VERSION ""

NS_ :

BS_:

BU_: XXX

BO_ 85 CID_PEUIZP: 8 XXX
 SG_ sig_yvqqxy : 40|1@1+ (1,0) [0|1] "" XXX
 SG_ sig_idcafi : 56|8@1+ (1,0) [0|255] "" XXX

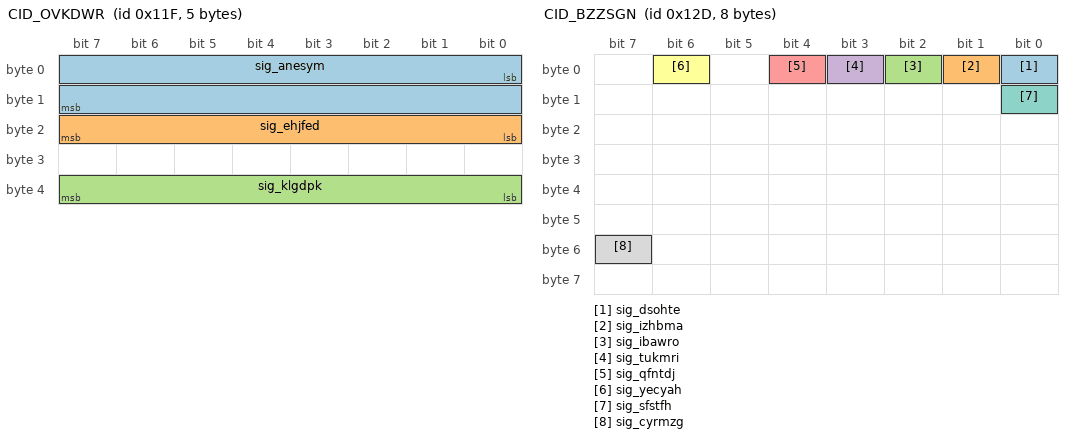
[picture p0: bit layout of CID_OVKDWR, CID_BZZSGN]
BO_ 287 CID_OVKDWR: 5 XXX
 SG_ sig_anesym : 0|16@1- (0.1,0) [-450|450] "" XXX
 SG_ sig_ehjfed : 16|8@1+ (4,0) [0|1020] "" XXX
 SG_ sig_klgdpk : 32|8@1+ (1,0) [0|255] "" XXX

BO_ 289 CID_AORLKS: 8 XXX
 SG_ sig_fkcpll : 0|12@1+ (1,0) [0|255] "" XXX

BO_ 301 CID_BZZSGN: 8 XXX
 SG_ sig_dsohte : 0|1@0+ (1,0) [0|1] "" XXX
 SG_ sig_izhbma : 1|1@0+ (1,0) [0|1] "" XXX
 SG_ sig_ibawro : 2|1@0+ (1,0) [0|1] "" XXX
 SG_ sig_tukmri : 3|1@0+ (1,0) [0|1] "" XXX
 SG_ sig_qfntdj : 4|1@0+ (1,0) [0|1] "" XXX
 SG_ sig_yecyah : 6|1@0+ (1,0) [0|1] "" XXX
 SG_ sig_sfstfh : 8|1@0+ (1,0) [0|1] "" XXX
 SG_ sig_cyrmzg : 55|1@0+ (1,0) [0|1] "" XXX

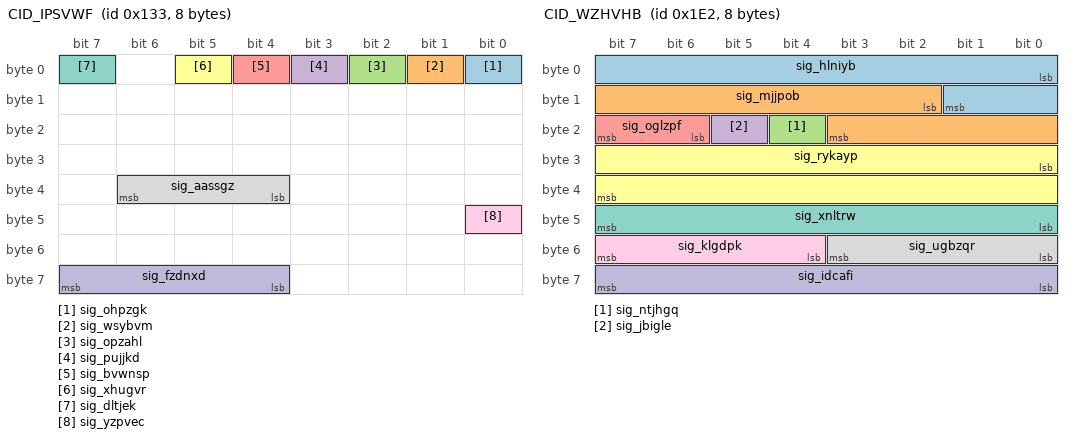
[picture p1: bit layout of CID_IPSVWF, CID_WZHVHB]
BO_ 307 CID_IPSVWF: 8 XXX
 SG_ sig_ohpzgk : 0|1@0+ (1,0) [0|1] "" XXX
 SG_ sig_wsybvm : 1|1@1+ (1,0) [0|1] "" XXX
 SG_ sig_opzahl : 2|1@1+ (1,0) [0|1] "" XXX
 SG_ sig_pujjkd : 3|1@1+ (1,0) [0|1] "" XXX
 SG_ sig_bvwnsp : 4|1@0+ (1,0) [0|1] "" XXX
 SG_ sig_xhugvr : 5|1@0+ (1,0) [0|1] "" XXX
 SG_ sig_dltjek : 7|1@0+ (1,0) [0|1] "" XXX
 SG_ sig_aassgz : 36|3@1+ (1,0) [0|7] "" XXX
 SG_ sig_yzpvec : 40|1@0+ (1,0) [0|1] "" XXX
 SG_ sig_fzdnxd : 63|4@0+ (1,0) [0|15] "" XXX

BO_ 482 CID_WZHVHB: 8 XXX
 SG_ sig_hlniyb : 0|10@1- (0.01,0) [0|5] "" XXX
 SG_ sig_mjjpob : 10|10@1- (0.01,0) [-5|0] "" XXX
 SG_ sig_ntjhgq : 20|1@0+ (1,0) [0|1] "" XXX
 SG_ sig_jbigle : 21|1@0+ (1,0) [0|1] "" XXX
 SG_ sig_oglzpf : 22|2@1+ (1,0) [0|1] "" XXX
 SG_ sig_rykayp : 24|16@1- (0.1,0) [-780|779.9] "" XXX
 SG_ sig_xnltrw : 47|8@0+ (1,0) [0|255] "" XXX
 SG_ sig_ugbzqr : 48|4@1+ (1,0) [0|15] "" XXX
 SG_ sig_klgdpk : 52|4@1+ (1,0) [0|15] "" XXX
 SG_ sig_idcafi : 56|8@1+ (1,0) [0|255] "" XXX

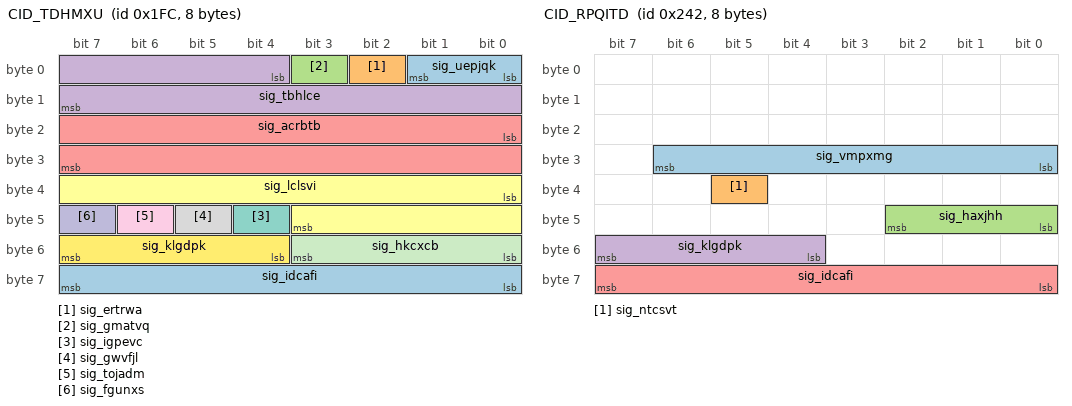
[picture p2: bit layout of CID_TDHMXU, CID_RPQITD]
BO_ 508 CID_TDHMXU: 8 XXX
 SG_ sig_uepjqk : 0|2@1+ (1,0) [0|1] "" XXX
 SG_ sig_ertrwa : 2|1@1+ (1,0) [0|1] "" XXX
 SG_ sig_gmatvq : 3|1@0+ (1,0) [0|1] "" XXX
 SG_ sig_tbhlce : 4|12@1- (1,0) [-2048|2047] "" XXX
 SG_ sig_acrbtb : 16|16@1- (0.1,0) [-780|779.9] "Deg" XXX
 SG_ sig_lclsvi : 32|12@1- (1,0) [0|63] "" XXX
 SG_ sig_igpevc : 44|1@0+ (1,0) [0|1] "" XXX
 SG_ sig_gwvfjl : 45|1@1+ (1,0) [0|255] "" XXX
 SG_ sig_tojadm : 46|1@1+ (1,0) [0|1] "" XXX
 SG_ sig_fgunxs : 47|1@0+ (1,0) [0|3] "" XXX
 SG_ sig_hkcxcb : 48|4@1+ (1,0) [0|15] "" XXX
 SG_ sig_klgdpk : 52|4@1+ (1,0) [0|15] "" XXX
 SG_ sig_idcafi : 56|8@1+ (1,0) [0|255] "" XXX

BO_ 578 CID_RPQITD: 8 XXX
 SG_ sig_vmpxmg : 30|7@0+ (1,0) [0|127] "" XXX
 SG_ sig_ntcsvt : 37|1@0+ (1,0) [0|1] "" XXX
 SG_ sig_haxjhh : 40|3@1+ (1,0) [0|7] "" XXX
 SG_ sig_klgdpk : 55|4@0+ (1,0) [0|15] "" XXX
 SG_ sig_idcafi : 56|8@1+ (1,0) [0|255] "" XXX

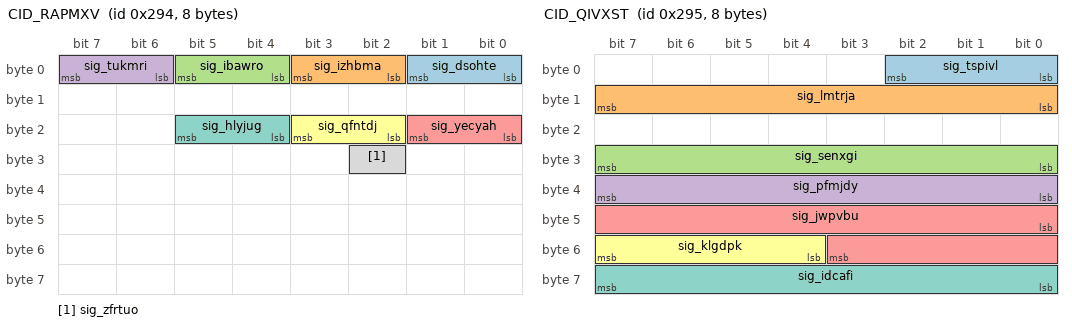
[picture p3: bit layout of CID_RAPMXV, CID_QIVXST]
BO_ 660 CID_RAPMXV: 8 XXX
 SG_ sig_dsohte : 1|2@0+ (1,0) [0|3] "" XXX
 SG_ sig_izhbma : 3|2@0+ (1,0) [0|3] "" XXX
 SG_ sig_ibawro : 5|2@0+ (1,0) [0|3] "" XXX
 SG_ sig_tukmri : 7|2@0+ (1,0) [0|3] "" XXX
 SG_ sig_yecyah : 17|2@0+ (1,0) [0|3] "" XXX
 SG_ sig_qfntdj : 19|2@0+ (1,0) [0|3] "" XXX
 SG_ sig_hlyjug : 21|2@0+ (1,0) [0|3] "" XXX
 SG_ sig_zfrtuo : 26|1@0+ (1,0) [0|1] "" XXX

BO_ 661 CID_QIVXST: 8 XXX
 SG_ sig_tspivl : 2|3@0+ (1,0) [0|7] "" XXX
 SG_ sig_lmtrja : 15|8@0+ (1,0) [0|255] "" XXX
 SG_ sig_senxgi : 31|8@0+ (1,0) [0|255] "" XXX
 SG_ sig_pfmjdy : 32|8@1+ (1,0) [0|255] "" XXX
 SG_ sig_jwpvbu : 40|12@1+ (1,0) [0|255] "" XXX
 SG_ sig_klgdpk : 52|4@1+ (1,0) [0|15] "" XXX
 SG_ sig_idcafi : 63|8@0+ (1,0) [0|255] "" XXX

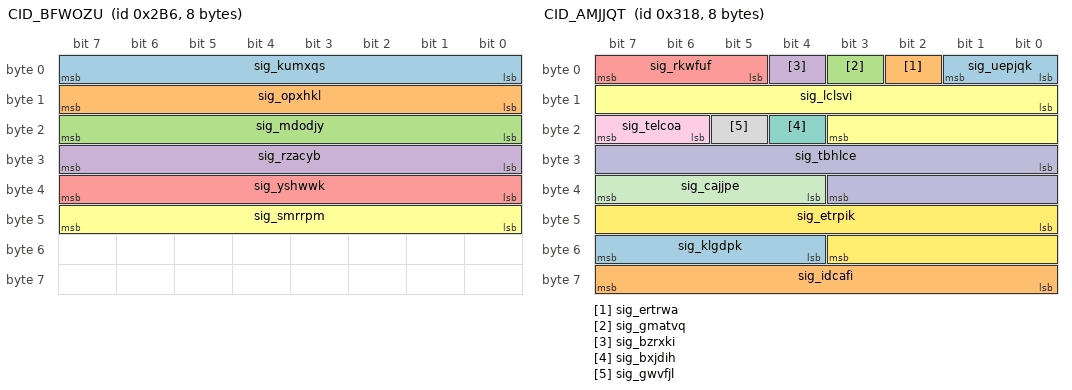
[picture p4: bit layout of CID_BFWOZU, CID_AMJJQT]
BO_ 694 CID_BFWOZU: 8 XXX
 SG_ sig_kumxqs : 7|8@0+ (1,0) [0|255] "" XXX
 SG_ sig_opxhkl : 15|8@0+ (1,0) [0|255] "" XXX
 SG_ sig_mdodjy : 23|8@0+ (1,0) [0|255] "" XXX
 SG_ sig_rzacyb : 31|8@0+ (1,0) [0|255] "" XXX
 SG_ sig_yshwwk : 39|8@0+ (1,0) [0|255] "" XXX
 SG_ sig_smrrpm : 47|8@0+ (1,0) [0|255] "" XXX

BO_ 790 CID_TVLKQR: 8 XXX
 SG_ sig_jftqug : 3|4@0+ (1,0) [0|1] "" XXX
 SG_ sig_bzrfrl : 4|2@1+ (1,0) [0|3] "" XXX
 SG_ sig_kjuwjn : 6|2@1+ (1,0) [0|3] "" XXX
 SG_ sig_vzitdr : 8|2@1+ (1,0) [0|3] "" XXX
 SG_ sig_mcuwzq : 10|1@1+ (1,0) [0|1] "" XXX
 SG_ sig_qhufxf : 11|4@1+ (1,0) [0|1] "" XXX
 SG_ sig_bguwph : 15|1@0+ (1,0) [0|1] "" XXX
 SG_ sig_rykayp : 16|11@1- (1,0) [-1024|1023] "" XXX
 SG_ sig_ntjhgq : 27|1@1+ (1,0) [0|1] "" XXX
 SG_ sig_jbigle : 28|1@1+ (1,0) [0|3] "" XXX
 SG_ sig_umrrjl : 29|1@0+ (1,0) [0|1] "" XXX
 SG_ sig_vdsypr : 30|1@0+ (1,0) [0|1] "" XXX
 SG_ sig_nazuvq : 31|1@0+ (1,0) [0|1] "" XXX
 SG_ sig_bxkagn : 32|2@1+ (1,0) [0|3] "" XXX
 SG_ sig_rsbhym : 34|2@1+ (1,0) [0|3] "" XXX
 SG_ sig_kmgogh : 36|4@1+ (1,0) [0|3] "" XXX
 SG_ sig_vwzhux : 40|8@1+ (5,-5) [-5|1270] "" XXX
 SG_ sig_emoqdt : 49|2@0+ (1,0) [0|3] "" XXX
 SG_ sig_bosbbj : 51|2@0+ (1,0) [0|3] "" XXX
 SG_ sig_klgdpk : 52|4@1+ (1,0) [0|15] "" XXX
 SG_ sig_idcafi : 56|8@1+ (1,0) [0|15] "" XXX

BO_ 792 CID_AMJJQT: 8 XXX
 SG_ sig_uepjqk : 0|2@1+ (1,0) [0|1] "" XXX
 SG_ sig_ertrwa : 2|1@1+ (1,0) [0|1] "" XXX
 SG_ sig_gmatvq : 3|1@1+ (1,0) [0|1] "" XXX
 SG_ sig_bzrxki : 4|1@1+ (1,0) [0|1] "" XXX
 SG_ sig_rkwfuf : 5|3@1+ (1,0) [0|1] "" XXX
 SG_ sig_lclsvi : 8|12@1- (1,0) [-2048|2047] "" XXX
 SG_ sig_bxjdih : 20|1@1+ (1,0) [0|1] "" XXX
 SG_ sig_gwvfjl : 21|1@1+ (1,0) [0|1] "" XXX
 SG_ sig_telcoa : 22|2@1+ (1,0) [0|15] "" XXX
 SG_ sig_tbhlce : 24|12@1- (1,0) [-2048|2047] "" XXX
 SG_ sig_cajjpe : 36|4@1+ (1,0) [0|15] "" XXX
 SG_ sig_etrpik : 40|12@1+ (1,0) [0|4095] "" XXX
 SG_ sig_klgdpk : 52|4@1+ (1,0) [0|15] "" XXX
 SG_ sig_idcafi : 56|8@1+ (1,0) [0|255] "" XXX

BO_ 813 CID_QEMSRD: 8 XXX
 SG_ sig_uzyciw : 0|9@1+ (0.5,0) [0|255.5] "" XXX
 SG_ sig_ffgucb : 9|1@1+ (1,0) [0|1] "" XXX
 SG_ sig_azbdjl : 10|3@1+ (1,0) [0|7] "" XXX
 SG_ sig_eayloy : 13|3@1+ (1,0) [0|7] "" XXX
 SG_ sig_ysnbtl : 16|1@1+ (1,0) [0|1] "" XXX
 SG_ sig_dsgkgk : 17|1@1+ (1,0) [0|1] "" XXX
 SG_ sig_gmatvq : 18|1@1+ (1,0) [0|1] "" XXX
 SG_ sig_btwoqg : 19|3@1+ (1,0) [0|1] "" XXX
 SG_ sig_siprhe : 22|1@0+ (1,0) [0|1] "" XXX
 SG_ sig_koehdn : 23|1@0+ (1,0) [0|1] "" XXX
 SG_ sig_vzitdr : 24|1@1+ (1,0) [0|1] "" XXX
 SG_ sig_jgahcb : 25|7@1+ (1,0) [0|127] "" XXX
 SG_ sig_wwvpby : 32|4@1+ (1,0) [0|15] "" XXX
 SG_ sig_sfoolh : 36|12@1+ (1,0) [0|4095] "" XXX
 SG_ sig_klgdpk : 48|4@1+ (1,0) [0|15] "" XXX
 SG_ sig_sxzzai : 55|4@0+ (1,0) [0|15] "" XXX
 SG_ sig_idcafi : 56|8@1+ (1,0) [0|255] "" XXX

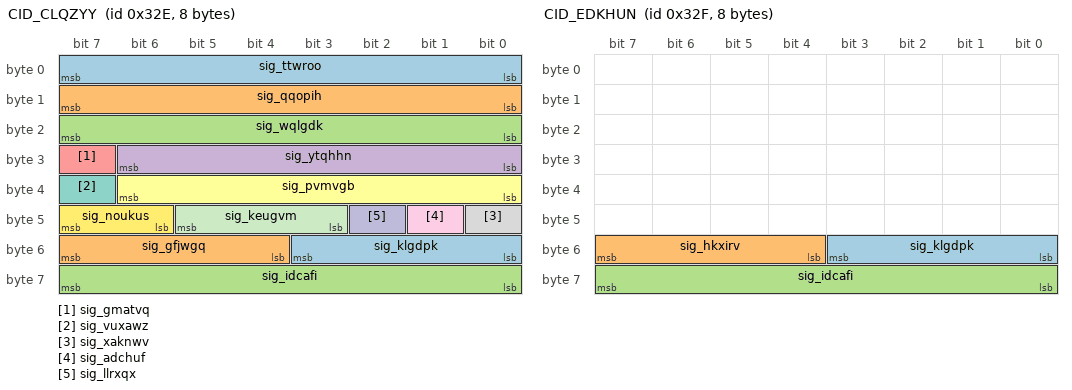
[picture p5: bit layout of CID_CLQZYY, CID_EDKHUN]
BO_ 814 CID_CLQZYY: 8 XXX
 SG_ sig_ttwroo : 0|8@1+ (0.05,-5) [-100|155] "" XXX
 SG_ sig_qqopih : 8|8@1+ (0.05,-5) [0|1.26] "" XXX
 SG_ sig_wqlgdk : 16|8@1+ (0.05,-5) [0|1.26] "" XXX
 SG_ sig_ytqhhn : 24|7@1+ (0.2,0) [0|12.7] "" XXX
 SG_ sig_gmatvq : 31|1@0+ (1,0) [0|1] "" XXX
 SG_ sig_pvmvgb : 32|7@1+ (0.2,-16) [0|12.7] "" XXX
 SG_ sig_vuxawz : 39|1@0+ (1,0) [0|1] "" XXX
 SG_ sig_xaknwv : 40|1@0+ (1,0) [0|1] "" XXX
 SG_ sig_adchuf : 41|1@0+ (1,0) [0|1] "" XXX
 SG_ sig_llrxqx : 42|1@1+ (1,0) [0|3] "" XXX
 SG_ sig_keugvm : 45|3@0+ (1,0) [0|1] "" XXX
 SG_ sig_noukus : 46|2@1+ (1,0) [0|3] "" XXX
 SG_ sig_klgdpk : 48|4@1+ (1,0) [0|15] "" XXX
 SG_ sig_gfjwgq : 55|4@0+ (1,0) [0|15] "" XXX
 SG_ sig_idcafi : 56|8@1+ (1,0) [0|255] "" XXX

BO_ 815 CID_EDKHUN: 8 XXX
 SG_ sig_klgdpk : 48|4@1+ (1,0) [0|15] "" XXX
 SG_ sig_hkxirv : 55|4@0+ (1,0) [0|15] "" XXX
 SG_ sig_idcafi : 56|8@1+ (1,0) [0|255] "" XXX

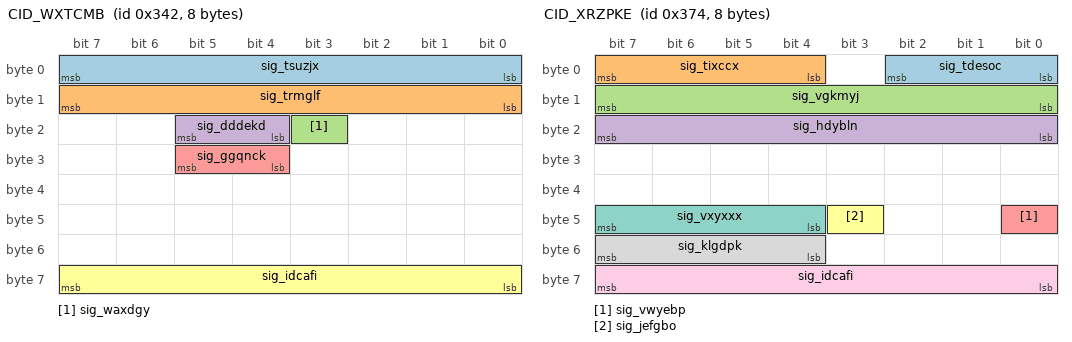
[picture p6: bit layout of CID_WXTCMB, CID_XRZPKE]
BO_ 834 CID_WXTCMB: 8 XXX
 SG_ sig_tsuzjx : 0|8@1+ (0.01,0) [0|2.55] "" XXX
 SG_ sig_trmglf : 8|8@1+ (0.01,0) [0|2.55] "" XXX
 SG_ sig_waxdgy : 19|1@1+ (1,0) [0|1] "" XXX
 SG_ sig_dddekd : 20|2@1+ (1,0) [0|255] "" XXX
 SG_ sig_ggqnck : 28|2@1+ (1,0) [0|1] "" XXX
 SG_ sig_idcafi : 56|8@1+ (1,0) [0|255] "" XXX

BO_ 884 CID_XRZPKE: 8 MRR
 SG_ sig_tdesoc : 2|3@0+ (1,0) [0|3] "" MRR
 SG_ sig_tixccx : 7|4@0+ (1,0) [0|15] "" MRR
 SG_ sig_vgkmyj : 15|8@0+ (0.1,-12) [0|255] "" MRR
 SG_ sig_hdybln : 23|8@0+ (1,-100) [0|255] "" MRR
 SG_ sig_vwyebp : 40|1@0+ (1,0) [0|3] "" MRR
 SG_ sig_jefgbo : 43|1@0+ (1,0) [0|1] "" XXX
 SG_ sig_vxyxxx : 44|4@1+ (1,0) [0|15] "" XXX
 SG_ sig_klgdpk : 52|4@1+ (1,0) [0|15] "" MRR
 SG_ sig_idcafi : 56|8@1+ (1,0) [0|255] "" MRR

BO_ 944 CID_PQEMVM: 8 XXX
 SG_ sig_zmoquy : 1|2@0+ (1,0) [0|3] "" XXX
 SG_ sig_bvrhwv : 2|1@0+ (1,0) [0|1] "" XXX
 SG_ sig_fxyaod : 4|2@0+ (1,0) [0|3] "" XXX
 SG_ sig_ccnwhs : 5|1@0+ (1,0) [0|1] "" XXX
 SG_ sig_fymxld : 6|1@0+ (1,0) [0|1] "" XXX
 SG_ sig_uztvmx : 7|1@0+ (1,0) [0|1] "" XXX
 SG_ sig_tvdrbx : 8|1@0+ (1,0) [0|1] "" XXX
 SG_ sig_yzbyys : 11|3@0+ (1,0) [0|7] "" XXX
 SG_ sig_vezpmo : 12|1@0+ (1,0) [0|1] "" XXX
 SG_ sig_ymhhtu : 14|2@0+ (1,0) [0|3] "" XXX
 SG_ sig_qjmenj : 15|1@0+ (1,0) [0|1] "" XXX
 SG_ sig_qjompr : 16|1@0+ (1,0) [0|1] "" XXX
 SG_ sig_helexa : 18|2@0+ (1,0) [0|3] "" XXX
 SG_ sig_gkwtmj : 19|1@0+ (1,0) [0|1] "" XXX
 SG_ sig_rcbhoi : 23|4@0+ (1,0) [0|15] "" XXX
 SG_ sig_yyxzsu : 24|28@1+ (1,0) [0|268435455] "" XXX
 SG_ sig_klgdpk : 52|4@1+ (1,0) [0|15] "" XXX
 SG_ sig_idcafi : 56|8@1+ (1,0) [0|255] "" XXX

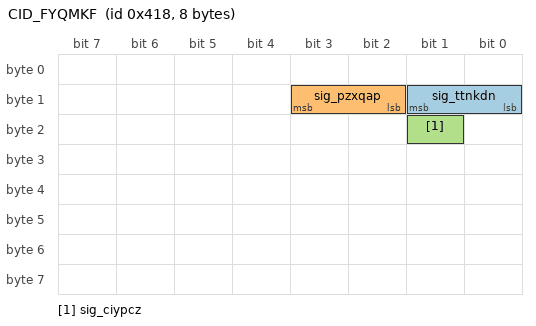
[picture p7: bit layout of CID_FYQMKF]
BO_ 1048 CID_FYQMKF: 8 XXX
 SG_ sig_ttnkdn : 9|2@0+ (1,0) [0|1] "" XXX
 SG_ sig_pzxqap : 11|2@0+ (1,0) [0|1] "" XXX
 SG_ sig_ciypcz : 17|1@0+ (1,0) [0|1] "" XXX

VAL_ 578 sig_haxjhh 4 "D" 2 "R" 3 "N" 1 "P";
VAL_ 790 sig_jftqug 11 "AutoFullBeamActive" 2 "AutoFullBeamInactive";
VAL_ 790 sig_bzrfrl 0 "GRAY" 1 "GREEN" 2 "YELLOW" 3 "RED";
VAL_ 790 sig_kjuwjn 3 "ALARM_AND_LKA" 2 "LKA" 1 "ALARM" 0 "DISABLE";
VAL_ 790 sig_rsbhym 0 "GRAY" 1 "GREEN" 2 "YELLOW" 3 "RED";
VAL_ 790 sig_emoqdt 0 "VIBRATION" 1 "AUDIO" 2 "AUDIO_AND_VIBRATION";
VAL_ 792 sig_uepjqk 0 "NotReady" 1 "Ready" 2 "Active" 3 "TemporaryFail";
VAL_ 813 sig_azbdjl 4 "4BAR" 3 "3BAR" 2 "2BAR" 1 "1BAR";
VAL_ 813 sig_btwoqg 0 "OFF" 2 "ACC_ON" 3 "ACC_ACTIVE" 5 "FORCE_ACCEL" 7 "ERROR";
VAL_ 813 sig_jgahcb 36 "ACC_ERROR" 22 "OVERRIDE" 12 "ENGAGE" 8 "DISENGAGE" 20 "ACC_ON" 32 "ACC_OFF" 48 "CHECK_GEAR_D" 16 "FORCE_ACCEL" 0 "NONE";
VAL_ 814 sig_keugvm 0 "Off" 1 "Passive" 2 "StandBy" 3 "ActiveControl" 4 "BrakeOnly" 5 "Override" 6 "Standstill" 7 "Failure";
VAL_ 814 sig_noukus 0 "Softoff" 1 "Fastoff" 2 "Immediateoff" 3 "Initial";
VAL_ 834 sig_dddekd 2 "SPORT" 1 "ECO" 0 "SNOW";
VAL_ 834 sig_ggqnck 3 "HEV" 2 "FORCE_EV" 1 "EV";
VAL_ 944 sig_fxyaod 0 "NOTPRESSED" 1 "DOWN_SETSPEED" 3 "UP_RESETSPEED";
